# irqctrl: IP-XACT component
VLNV spiritconsortium.org:Leon2RTL:irqctrl:1.3
Interrupt controller with improved register description

## Bus interfaces (logical=physical port)
APBClk: slave spiritconsortium.org:busdef.clock:clock:1.0
  CLK=clk
APBReset: slave spiritconsortium.org:busdef.reset:reset:1.0
  RESETn=rst
ambaAPB: slave amba.com:AMBA2:APB:r2p0_4, memory map ambaAPB
  PSELx=psel, PENABLE=penable, PADDR=paddr, PWRITE=pwrite, PWDATA=pwdata, PRDATA=prdata, PCLK=clk, PRESETn=rst
MasterInt: master spiritconsortium.org:busdef.leon2:IntProc:v1.0
  IRL=irlout, IRQVEC=irlin, INTack=intack
SlaveInt14: slave spiritconsortium.org:busdef.interrupt:interrupt:1.0
  IRQ=irq[14:14]
SlaveInt13: slave spiritconsortium.org:busdef.interrupt:interrupt:1.0
  IRQ=irq[13:13]
SlaveInt12: slave spiritconsortium.org:busdef.interrupt:interrupt:1.0
  IRQ=irq[12:12]
SlaveInt11: slave spiritconsortium.org:busdef.interrupt:interrupt:1.0
  IRQ=irq[11:11]
SlaveInt10: slave spiritconsortium.org:busdef.interrupt:interrupt:1.0
  IRQ=irq[10:10]
SlaveInt9: slave spiritconsortium.org:busdef.interrupt:interrupt:1.0
  IRQ=irq[9:9]
SlaveInt8: slave spiritconsortium.org:busdef.interrupt:interrupt:1.0
  IRQ=irq[8:8]
SlaveInt7: slave spiritconsortium.org:busdef.interrupt:interrupt:1.0
  IRQ=irq[7:7]
SlaveInt6: slave spiritconsortium.org:busdef.interrupt:interrupt:1.0
  IRQ=irq[6:6]
SlaveInt5: slave spiritconsortium.org:busdef.interrupt:interrupt:1.0
  IRQ=irq[5:5]
SlaveInt4: slave spiritconsortium.org:busdef.interrupt:interrupt:1.0
  IRQ=irq[4:4]
SlaveInt3: slave spiritconsortium.org:busdef.interrupt:interrupt:1.0
  IRQ=irq[3:3]
SlaveInt2: slave spiritconsortium.org:busdef.interrupt:interrupt:1.0
  IRQ=irq[2:2]
SlaveInt1: slave spiritconsortium.org:busdef.interrupt:interrupt:1.0
  IRQ=irq[1:1]
SlaveInt0: slave spiritconsortium.org:busdef.interrupt:interrupt:1.0
  IRQ=irq[0:0]

## Ports
in clk
in rst
in psel
in penable
in paddr[31:0]
in pwrite
in pwdata[31:0]
out prdata[31:0]
in irq[14:0]
in intack
in irlin[3:0]
out irlout[3:0]

## Address spaces and blocks
ambaAPB.ablock: base 0, range 64, width 32

## Registers
Registers are 32-bit, read-write, reset 0x0 unless marked. A register's access mark holds for its fields unless they carry their own. Offsets are from the block's base; lines under a group give offsets from that group; [hi:lo] are bit positions; {n}, {i} and the like mark numbered series; 'fields as' and 'values as' point back to an identical list; <NAME> marks a mode.

## ambaAPB.ablock
Base 0x00000000
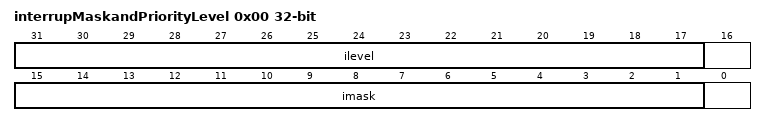
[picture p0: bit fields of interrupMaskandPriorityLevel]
0x00 interrupMaskandPriorityLevel (reset mask 0x1FFFF) — Interrupt Mask and Priority
  [31:17] ilevel — Indicates if an interrupt belongs to priority level 1 (bit=1) or 0 (bit=0)
  [15:1] imask — Indicates if an interrupt is masked (bit=0) or enabled (bit=1)
0x04 interruptPendingRegister (reset mask 0xFFFF0001) — Indicates if an interrupt is pending
  [15:1] ipend — Indicates if an interrupt is pending (bit=1)
0x08 interruptForceRegister (reset mask 0xFFFF0001) — Indicates if an interrupt is being forced
  [15:1] iforce — Indicates if an interrupt is being forced (bit=1)
0x0C interruptClearRegister wo reset not defined — If written with a '1', will clear corresponding bit(s) in interrupt pending register.
  [15:1] iclear rw write-1-clears
0x0C interruptClearRegisterRead ro — A read returns X.
0x10 interruptReadClearPendingRegister (reset mask 0xFFFFFFF0)
  [3:0] pendIntEncode ro read-modifies — Pending encoded interrupt

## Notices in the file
Copyright (c) 2006, 2008, 2009 The SPIRIT Consortium.
This work forms part of a deliverable of The SPIRIT Consortium.
Use of these materials are governed by the legal terms and conditions
outlined in the disclaimer available from www.spiritconsortium.org.
This source file is provided on an AS IS basis.  The SPIRIT
Consortium disclaims any warranty express or implied including
any warranty of merchantability and fitness for use for a
particular purpose.
The user of the source file shall indemnify and hold The SPIRIT
Consortium and its members harmless from any damages or liability.
